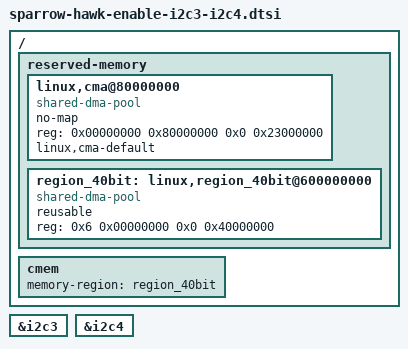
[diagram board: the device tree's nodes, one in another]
&i2c3 {
	status = "okay";
};
&i2c4 {
	status = "okay";
};

/ {
	reserved-memory {
		/* global autoconfigured region for contiguous allocations */
		linux,cma@80000000 {
			compatible = "shared-dma-pool";
			//reusable;
			no-map;
			reg = <0x00000000 0x80000000 0x0 0x23000000>;
			linux,cma-default;
		};
	
		region_40bit: linux,region_40bit@600000000 {
			compatible = "shared-dma-pool";
			reusable;
			reg = <0x6 0x00000000 0x0 0x40000000>;
		};
	
	};
	cmem {
		memory-region = <&region_40bit>;
	};
};

